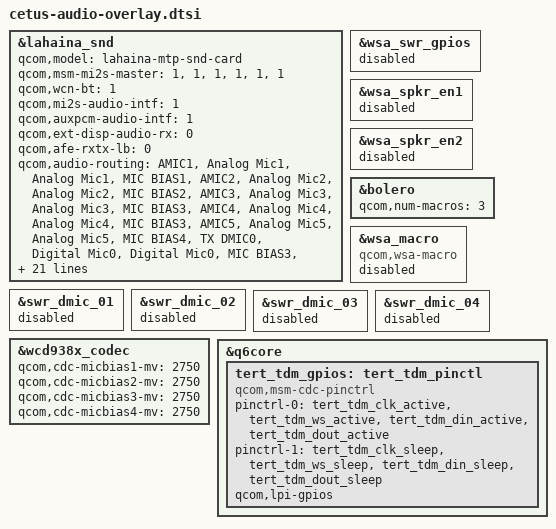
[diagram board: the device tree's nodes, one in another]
#include "lahaina-audio-overlay.dtsi"

&lahaina_snd {
	qcom,model = "lahaina-mtp-snd-card";
	qcom,msm-mi2s-master = <1>, <1>, <1>, <1>, <1>, <1>;
	qcom,wcn-bt = <1>;
	qcom,mi2s-audio-intf = <1>;
	qcom,auxpcm-audio-intf = <1>;
	qcom,ext-disp-audio-rx = <0>;
	qcom,afe-rxtx-lb = <0>;
	qcom,audio-routing =
		"AMIC1", "Analog Mic1",
		"Analog Mic1", "MIC BIAS1",
		"AMIC2", "Analog Mic2",
		"Analog Mic2", "MIC BIAS2",
		"AMIC3", "Analog Mic3",
		"Analog Mic3", "MIC BIAS3",
		"AMIC4", "Analog Mic4",
		"Analog Mic4", "MIC BIAS3",
		"AMIC5", "Analog Mic5",
		"Analog Mic5", "MIC BIAS4",
		"TX DMIC0", "Digital Mic0",
		"Digital Mic0", "MIC BIAS3",
		"TX DMIC1", "Digital Mic1",
		"Digital Mic1", "MIC BIAS3",
		"TX DMIC2", "Digital Mic2",
		"Digital Mic2", "MIC BIAS1",
		"TX DMIC3", "Digital Mic3",
		"Digital Mic3", "MIC BIAS1",
		"TX DMIC4", "Digital Mic4",
		"Digital Mic4", "MIC BIAS4",
		"TX DMIC5", "Digital Mic5",
		"Digital Mic5", "MIC BIAS4",
		"IN1_HPHL", "HPHL_OUT",
		"IN2_HPHR", "HPHR_OUT",
		"IN3_AUX", "AUX_OUT",
		"RX_TX DEC0_INP", "TX DEC0 MUX",
		"RX_TX DEC1_INP", "TX DEC1 MUX",
		"RX_TX DEC2_INP", "TX DEC2 MUX",
		"RX_TX DEC3_INP", "TX DEC3 MUX",
		"TX SWR_INPUT", "WCD_TX_OUTPUT",
		"VA SWR_INPUT", "VA_SWR_CLK",
		"VA SWR_INPUT", "WCD_TX_OUTPUT",
		"VA_AIF1 CAP", "VA_SWR_CLK",
		"VA_AIF2 CAP", "VA_SWR_CLK",
		"VA_AIF3 CAP", "VA_SWR_CLK";

	qcom,msm-mbhc-hphl-swh = <0>;
	qcom,msm-mbhc-gnd-swh = <0>;
	qcom,wsa-max-devs = <0>;
	qcom,swr-dmic-max-devs = <0>;
	qcom,msm-mbhc-usbc-audio-supported = <1>;
	qcom,tert-mi2s-gpios = <&tert_tdm_gpios>;
};

&wsa_swr_gpios {
	status = "disabled";
};

&wsa_spkr_en1 {
	status = "disabled";
};

&wsa_spkr_en2 {
	status = "disabled";
};

&bolero {
	qcom,num-macros = <3>;
};

&wsa_macro {
	compatible = "qcom,wsa-macro";
	status = "disabled";
};

&swr_dmic_01 {
	status = "disabled";
};

&swr_dmic_02 {
	status = "disabled";
};

&swr_dmic_03 {
	status = "disabled";
};

&swr_dmic_04 {
	status = "disabled";
};

&wcd938x_codec {
	qcom,cdc-micbias1-mv = <2750>;
	qcom,cdc-micbias2-mv = <2750>;
	qcom,cdc-micbias3-mv = <2750>;
	qcom,cdc-micbias4-mv = <2750>;
};

&q6core {
	tert_tdm_gpios: tert_tdm_pinctl {
		compatible = "qcom,msm-cdc-pinctrl";
		pinctrl-names = "aud_active", "aud_sleep";
		pinctrl-0 = <&tert_tdm_clk_active &tert_tdm_ws_active
			&tert_tdm_din_active &tert_tdm_dout_active>;
		pinctrl-1 = <&tert_tdm_clk_sleep &tert_tdm_ws_sleep
			&tert_tdm_din_sleep &tert_tdm_dout_sleep>;
		qcom,lpi-gpios;
		#gpio-cells = <0>;
	};
};
